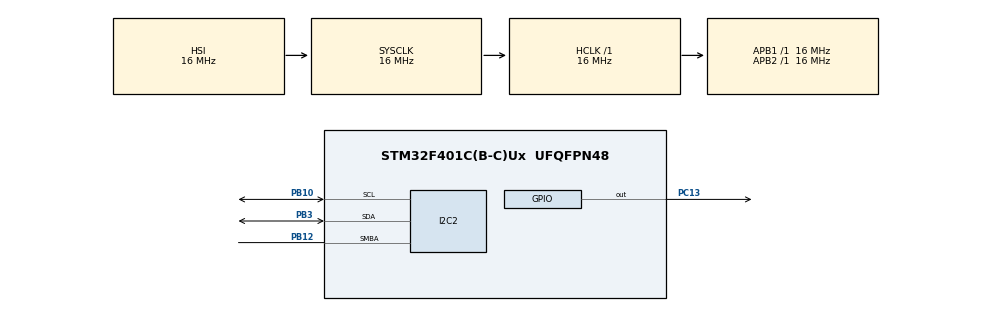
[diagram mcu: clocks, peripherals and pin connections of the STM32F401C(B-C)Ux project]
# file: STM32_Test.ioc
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Mcu.Family=STM32F4
Mcu.Name=STM32F401C(B-C)Ux
Mcu.Package=UFQFPN48
NVIC.PriorityGroup=NVIC_PRIORITYGROUP_4
PB10.Mode=SMBus-Alert-mode
PB10.Signal=I2C2_SCL
PB12.Mode=SMBus-Alert-mode
PB12.Signal=I2C2_SMBA
PB3.Mode=SMBus-Alert-mode
PB3.Signal=I2C2_SDA
PC13-ANTI_TAMP.Signal=GPIO_Output
ProjectManager.HeapSize=0x200
ProjectManager.StackSize=0x400
ProjectManager.TargetToolchain=STM32CubeIDE
RCC.AHBFreq_Value=16000000
RCC.APB1Freq_Value=16000000
RCC.APB2Freq_Value=16000000
RCC.CortexFreq_Value=16000000
RCC.HSE_VALUE=25000000
RCC.HSI_VALUE=16000000
RCC.LSE_VALUE=32768
RCC.SYSCLKFreq_VALUE=16000000
RCC.VCOOutputFreq_Value=192000000
board=custom

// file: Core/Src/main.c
/* USER CODE BEGIN Header */
/**
 ******************************************************************************
 * @file           : main.c
 * @brief          : Main program body
 ******************************************************************************
 * @attention
 *
 * Copyright (c) 2024 STMicroelectronics.
 * All rights reserved.
 *
 * This software is licensed under terms that can be found in the LICENSE file
 * in the root directory of this software component.
 * If no LICENSE file comes with this software, it is provided AS-IS.
 *
 ******************************************************************************
 */
/* USER CODE END Header */
#include "main.h"

SMBUS_HandleTypeDef hsmbus2;

void SystemClock_Config(void);
static void MX_GPIO_Init(void);
static void MX_I2C2_SMBUS_Init(void);

int main(void)
{
  /* USER CODE BEGIN 1 */
	tedsttstst
	    tedsttstst
	    tedsttstst

	    tedsttstst
	    tedsttstst
		tedsttstst
		    tedsttstst
		    tedsttstst

		    tedsttstst
		    tedsttstst

  /* USER CODE END 1 */

  /* MCU Configuration--------------------------------------------------------*/

  /* Reset of all peripherals, Initializes the Flash interface and the Systick. */
  HAL_Init();

  /* Configure the system clock */
  SystemClock_Config();

  /* Initialize all configured peripherals */
  MX_GPIO_Init();
  MX_I2C2_SMBUS_Init();

  /* Infinite loop */
  while (1)
  {

  }
}

void SystemClock_Config(void)
{
  RCC_OscInitTypeDef RCC_OscInitStruct = {0};
  RCC_ClkInitTypeDef RCC_ClkInitStruct = {0};

  /** Configure the main internal regulator output voltage
  */
  __HAL_RCC_PWR_CLK_ENABLE();
  __HAL_PWR_VOLTAGESCALING_CONFIG(PWR_REGULATOR_VOLTAGE_SCALE2);

  /** Initializes the RCC Oscillators according to the specified parameters
  * in the RCC_OscInitTypeDef structure.
  */
  RCC_OscInitStruct.OscillatorType = RCC_OSCILLATORTYPE_HSI;
  RCC_OscInitStruct.HSIState = RCC_HSI_ON;
  RCC_OscInitStruct.HSICalibrationValue = RCC_HSICALIBRATION_DEFAULT;
  RCC_OscInitStruct.PLL.PLLState = RCC_PLL_NONE;
  if (HAL_RCC_OscConfig(&RCC_OscInitStruct) != HAL_OK)
  {
    Error_Handler();
  }

  /** Initializes the CPU, AHB and APB buses clocks
  */
  RCC_ClkInitStruct.ClockType = RCC_CLOCKTYPE_HCLK|RCC_CLOCKTYPE_SYSCLK
                              |RCC_CLOCKTYPE_PCLK1|RCC_CLOCKTYPE_PCLK2;
  RCC_ClkInitStruct.SYSCLKSource = RCC_SYSCLKSOURCE_HSI;
  RCC_ClkInitStruct.AHBCLKDivider = RCC_SYSCLK_DIV1;
  RCC_ClkInitStruct.APB1CLKDivider = RCC_HCLK_DIV1;
  RCC_ClkInitStruct.APB2CLKDivider = RCC_HCLK_DIV1;

  if (HAL_RCC_ClockConfig(&RCC_ClkInitStruct, FLASH_LATENCY_0) != HAL_OK)
  {
    Error_Handler();
  }
}

static void MX_I2C2_SMBUS_Init(void)
{

  hsmbus2.Instance = I2C2;
  hsmbus2.Init.ClockSpeed = 100000;
  hsmbus2.Init.OwnAddress1 = 0;
  hsmbus2.Init.AddressingMode = SMBUS_ADDRESSINGMODE_7BIT;
  hsmbus2.Init.DualAddressMode = SMBUS_DUALADDRESS_DISABLE;
  hsmbus2.Init.OwnAddress2 = 0;
  hsmbus2.Init.GeneralCallMode = SMBUS_GENERALCALL_DISABLE;
  hsmbus2.Init.NoStretchMode = SMBUS_NOSTRETCH_DISABLE;
  hsmbus2.Init.PacketErrorCheckMode = SMBUS_PEC_DISABLE;
  hsmbus2.Init.PeripheralMode = SMBUS_PERIPHERAL_MODE_SMBUS_SLAVE;
  if (HAL_SMBUS_Init(&hsmbus2) != HAL_OK)
  {
    Error_Handler();
  }

  /** configuration Alert Mode
  */
  if (HAL_SMBUS_EnableAlert_IT(&hsmbus2) != HAL_OK)
  {
    Error_Handler();
  }

}

static void MX_GPIO_Init(void)
{
  GPIO_InitTypeDef GPIO_InitStruct = {0};

  /* GPIO Ports Clock Enable */
  __HAL_RCC_GPIOC_CLK_ENABLE();
  __HAL_RCC_GPIOB_CLK_ENABLE();

  /*Configure GPIO pin Output Level */
  HAL_GPIO_WritePin(GPIOC, GPIO_PIN_13, GPIO_PIN_RESET);

  /*Configure GPIO pin : PC13 */
  GPIO_InitStruct.Pin = GPIO_PIN_13;
  GPIO_InitStruct.Mode = GPIO_MODE_OUTPUT_PP;
  GPIO_InitStruct.Pull = GPIO_NOPULL;
  GPIO_InitStruct.Speed = GPIO_SPEED_FREQ_LOW;
  HAL_GPIO_Init(GPIOC, &GPIO_InitStruct);

}

void Error_Handler(void)
{
  __disable_irq();
  while (1)
  {
  }
}
